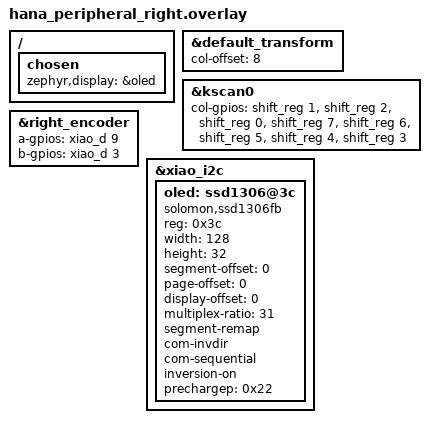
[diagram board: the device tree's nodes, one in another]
#include "hana.dtsi"

&default_transform {
    col-offset = <8>;
};

&kscan0 {
    col-gpios
        = <&shift_reg 1 (GPIO_ACTIVE_HIGH)>
        , <&shift_reg 2 (GPIO_ACTIVE_HIGH)>
        , <&shift_reg 0 (GPIO_ACTIVE_HIGH)>
        , <&shift_reg 7 (GPIO_ACTIVE_HIGH)>
        , <&shift_reg 6 (GPIO_ACTIVE_HIGH)>
        , <&shift_reg 5 (GPIO_ACTIVE_HIGH)>
        , <&shift_reg 4 (GPIO_ACTIVE_HIGH)>
        , <&shift_reg 3 (GPIO_ACTIVE_HIGH)>
        ;
};

&right_encoder {
    status = "okay";
    a-gpios = <&xiao_d 9 (GPIO_ACTIVE_HIGH | GPIO_PULL_UP)>;
    b-gpios = <&xiao_d 3 (GPIO_ACTIVE_HIGH | GPIO_PULL_UP)>;
};

&xiao_i2c {
    oled: ssd1306@3c {
        compatible = "solomon,ssd1306fb";
        reg = <0x3c>;
        width = <128>;
        height = <32>;
        segment-offset = <0>;
        page-offset = <0>;
        display-offset = <0>;
        multiplex-ratio = <31>;
        segment-remap;
        com-invdir;
        com-sequential;
        inversion-on;
        prechargep = <0x22>;
    };
};

/ {
    chosen {
        zephyr,display = &oled;
    };
};
